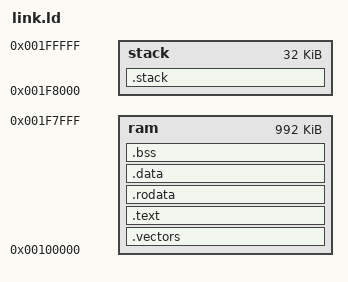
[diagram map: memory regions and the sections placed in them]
/* Copyright lowRISC contributors.
   Licensed under the Apache License, Version 2.0, see LICENSE for details.
   SPDX-License-Identifier: Apache-2.0 */

OUTPUT_ARCH(riscv)

MEMORY
{
    /* 992 kB should be enough for anybody... */
    ram         : ORIGIN = 0x00100000, LENGTH = 0xF8000 /* 992 kB  0xF8000*/ /* AZ=92 kB 0x15800*/
    stack       : ORIGIN = 0x001F8000, LENGTH = 0x8000  /* 32 kB 0x8000 0x001F8000 */ /* AZ=8 kB 0x2000 */
}

/* Stack information variables */
_min_stack      = 0x2000;   /* 8K - minimum stack space to reserve */
_stack_len     = LENGTH(stack);
_stack_start   = ORIGIN(stack) + LENGTH(stack);

SECTIONS
{
    .vectors :
    {
        . = ALIGN(4);
        KEEP(*(.vectors))
    } > ram

    .text : {
        . = ALIGN(4);
        *(.text)
        *(.text.*)
    }  > ram

    .rodata : {
        . = ALIGN(4);
        *(.rodata);
        *(.rodata.*)
    } > ram

    .data : {
        . = ALIGN(4);
        *(.data);
        *(.data.*)
    } > ram

    .bss :
    {
        . = ALIGN(4);
        _bss_start = .;
        *(.bss)
        *(.bss.*)
        *(COMMON)
        _bss_end = .;
    } > ram

    /* ensure there is enough room for stack */
    .stack (NOLOAD): {
        . = ALIGN(4);
        . = . + _min_stack ;
        . = ALIGN(4);
        stack = . ;
        _stack = . ;
    } > stack
}
